# APM32F411 register map
Vendor: Geehy; File version: 2024.11.05
CPU: CM4 r1p0, little endian, 3 interrupt priority bits
Registers are 32-bit, read-write, reset 0x0 unless marked. A register's access mark holds for its fields unless they carry their own. Offsets are from the block's base; [hi:lo] are bit positions; {n}, {i} and the like mark numbered series.

## DWT — Data Watchpoint and Trace
Base 0xE0001000
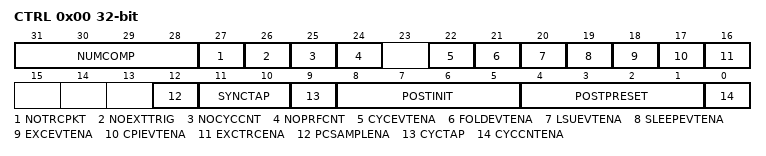
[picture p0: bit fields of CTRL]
0x00 CTRL — Control Register
  [31:28] NUMCOMP — Number of comparators implemented
  [27] NOTRCPKT — Indicates no trace packets are implemented
  [26] NOEXTTRIG — Indicates no external match trigger is implemented
  [25] NOCYCCNT — Indicates no cycle counter is implemented
  [24] NOPRFCNT — Indicates no profiling counters are implemented
  [22] CYCEVTENA — Enables cycle event
  [21] FOLDEVTENA — Enables folded instruction event
  [20] LSUEVTENA — Enables LSU counter event
  [19] SLEEPEVTENA — Enables sleep event
  [18] EXCEVTENA — Enables exception overhead event
  [17] CPIEVTENA — Enables CPI counter event
  [16] EXCTRCENA — Enables exception tracing
  [12] PCSAMPLENA — Enables program counter sampling
  [11:10] SYNCTAP — Synchronization tap
  [9] CYCTAP — Cycle count tap
  [8:5] POSTINIT — Post-initialization value
  [4:1] POSTPRESET — Post-scaler preset value
  [0] CYCCNTENA — Enables cycle counter
0x04 CYCCNT — Cycle Count Register
  [31:0] CYCCNT — Cycle counter value
0x08 CPICNT — CPI Count Register
  [7:0] CPICNT — CPI counter value
0x0C EXCCNT — Exception Overhead Count Register
  [7:0] EXCCNT — Exception overhead counter value
0x10 SLEEPCNT — Sleep Count Register
  [7:0] SLEEPCNT — Sleep counter value
0x14 LSUCNT — LSU Count Register
  [7:0] LSUCNT — LSU counter value
0x18 FOLDCNT — Folded-instruction Count Register
  [7:0] FOLDCNT — Folded-instruction counter value
0x1C PCSR ro — Program Counter Sample Register
  [31:0] PCSR — Program counter sample value
{0x20+0x10*i} COMP{i} (i=0..3) reset not defined — Comparator Registers
  [31:0] COMP — Comparator value
{0x24+0x10*i} MASK{i} (i=0..3) reset not defined — Mask Registers
  [4:0] MASK — Mask value
{0x28+0x10*i} FUNCTION{i} (i=0..3) reset not defined — Function Registers
  [31:0] FUNCTION — Function settings

## TPI — Trace Port Interface (aka TPIU - Trace Port Interface Unit)
Base 0xE0040000
0x00 SSPSR ro — Supported Parallel Port Size Register
  [31:0] PARALLEL_SIZE — Supported parallel port size (aka SWIDTH)
0x04 CSPSR — Current Parallel Port Size Register
  [31:0] PARALLEL_SIZE — Current parallel port size (aka CWIDTH)
0x10 ACPR — Asynchronous Clock Prescaler Register
  [12:0] PRESCALER — Prescaler value (aka SWOSCALER)
0xF0 SPPR — Selected Pin Protocol Register
  [1:0] TXMODE — Transmit protocol mode
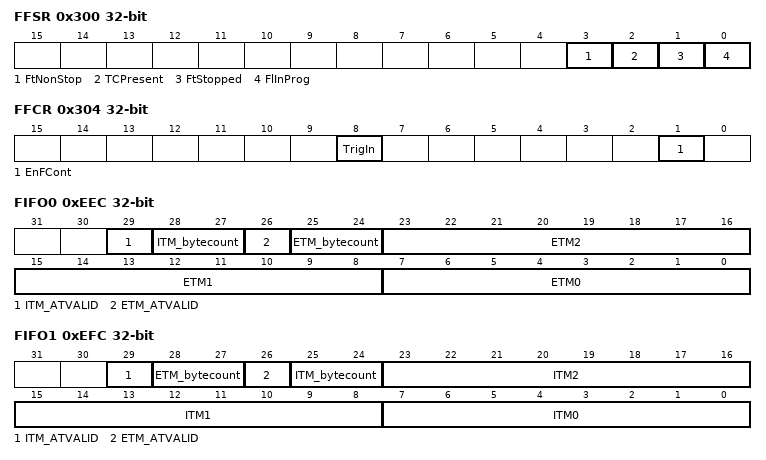
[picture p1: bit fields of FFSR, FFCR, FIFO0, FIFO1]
0x300 FFSR ro — Formatter and Flush Status Register
  [3] FtNonStop — Formatter non-stop mode
  [2] TCPresent — Trace Control Present
  [1] FtStopped — Formatter stopped
  [0] FlInProg — Flush in progress
0x304 FFCR — Formatter and Flush Control Register
  [8] TrigIn — Trigger input enabled
  [1] EnFCont — Enable continuous formatting
0xEE8 TRIGGER ro
  [0] TRIGGER — Trigger input value
0xEEC FIFO0 ro — Integration ETM Data
  [29] ITM_ATVALID — ITM data valid
  [28:27] ITM_bytecount
  [26] ETM_ATVALID — ETM data valid
  [25:24] ETM_bytecount
  [23:16] ETM2 — ETM byte 2
  [15:8] ETM1 — ETM byte 1
  [7:0] ETM0 — ETM byte 0
0xEF0 ITATBCTR2 ro — Integration Test ATB Control Register 2
  [0] ATREADY — Sets the value of both the ETM and ITM ATREADY outputs, if the TPI is in integration test mode
0xEF8 ITATBCTR0 ro — Integration Test ATB Control Register 0
  [0] ATVALID — A read of this bit returns the value of ATVALIDS1 OR-ed with ATVALIDS2
0xEFC FIFO1 ro — Integration ITM Data
  [29] ITM_ATVALID — ITM data valid
  [28:27] ETM_bytecount
  [26] ETM_ATVALID — ETM data valid
  [25:24] ITM_bytecount
  [23:16] ITM2 — ITM byte 2
  [15:8] ITM1 — ITM byte 1
  [7:0] ITM0 — ITM byte 0
0xF00 ITCTRL — Integration Mode Control Register
  [1:0] MODE — Integration mode enable
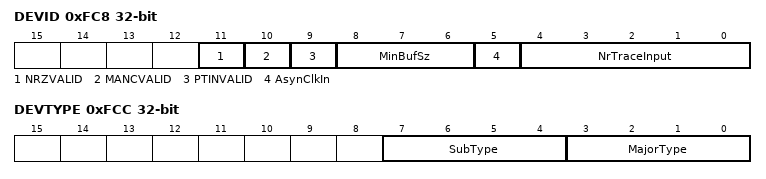
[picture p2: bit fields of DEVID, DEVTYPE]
0xFC8 DEVID ro — TPIU_DEVID
  [11] NRZVALID — Indicates NRZ encoding is valid
  [10] MANCVALID — Indicates Manchester encoding is valid
  [9] PTINVALID — Indicates that Parallel Trace is invalid
  [8:6] MinBufSz — Minimum buffer size supported
  [5] AsynClkIn — Indicates support for asynchronous clock input
  [4:0] NrTraceInput — Number of trace inputs supported
0xFCC DEVTYPE ro — TPIU_DEVTYPE
  [7:4] SubType — Sub-type of the device
  [3:0] MajorType — Major device type
